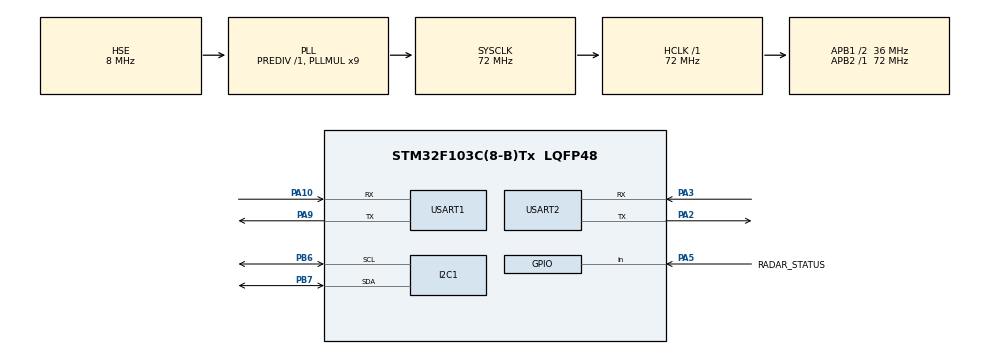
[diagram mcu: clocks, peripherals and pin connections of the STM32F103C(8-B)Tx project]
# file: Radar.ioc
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I2C1.I2C_Mode=I2C_Fast
Mcu.Family=STM32F1
Mcu.Name=STM32F103C(8-B)Tx
Mcu.Package=LQFP48
NVIC.PriorityGroup=NVIC_PRIORITYGROUP_4
NVIC.USART2_IRQn=true\:0\:0\:false\:false\:true\:true\:true\:true
PA10.Mode=Asynchronous
PA10.Signal=USART1_RX
PA13.Mode=Serial_Wire
PA13.Signal=SYS_JTMS-SWDIO
PA14.Mode=Serial_Wire
PA14.Signal=SYS_JTCK-SWCLK
PA2.Mode=Asynchronous
PA2.Signal=USART2_TX
PA3.Mode=Asynchronous
PA3.Signal=USART2_RX
PA5.GPIO_Label=RADAR_STATUS
PA5.GPIO_PuPd=GPIO_PULLDOWN
PA5.Signal=GPIO_Input
PA9.Mode=Asynchronous
PA9.Signal=USART1_TX
PB6.Mode=I2C
PB6.Signal=I2C1_SCL
PB7.Mode=I2C
PB7.Signal=I2C1_SDA
PD0-OSC_IN.Mode=HSE-External-Oscillator
PD0-OSC_IN.Signal=RCC_OSC_IN
PD1-OSC_OUT.Mode=HSE-External-Oscillator
PD1-OSC_OUT.Signal=RCC_OSC_OUT
ProjectManager.HeapSize=0x200
ProjectManager.StackSize=0x400
ProjectManager.TargetToolchain=CMake
RCC.AHBFreq_Value=72000000
RCC.APB1CLKDivider=RCC_HCLK_DIV2
RCC.APB1Freq_Value=36000000
RCC.APB1TimFreq_Value=72000000
RCC.APB2Freq_Value=72000000
RCC.APB2TimFreq_Value=72000000
RCC.HCLKFreq_Value=72000000
RCC.PLLMUL=RCC_PLL_MUL9
RCC.PLLSourceVirtual=RCC_PLLSOURCE_HSE
RCC.SYSCLKFreq_VALUE=72000000
RCC.SYSCLKSource=RCC_SYSCLKSOURCE_PLLCLK
RCC.USBFreq_Value=72000000
USART1.VirtualMode=VM_ASYNC
USART2.VirtualMode=VM_ASYNC
board=custom

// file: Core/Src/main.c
/* USER CODE BEGIN Header */
/**
  ******************************************************************************
  * @file           : main.c
  * @brief          : Main program body
  ******************************************************************************
  * @attention
  *
  * Copyright (c) 2026 STMicroelectronics.
  * All rights reserved.
  *
  * This software is licensed under terms that can be found in the LICENSE file
  * in the root directory of this software component.
  * If no LICENSE file comes with this software, it is provided AS-IS.
  *
  ******************************************************************************
  */
/* USER CODE END Header */
#include "main.h"

/* USER CODE BEGIN Includes */
#include "alert_led.h"
#include "oled_ui.h"
#include "radar_service.h"
#include "uart1_summary.h"
/* USER CODE END Includes */

I2C_HandleTypeDef hi2c1;

UART_HandleTypeDef huart1;
UART_HandleTypeDef huart2;

/* USER CODE BEGIN PV */
/* 雷达业务共享状态（雷达解析/OLED/UART1 汇总共用）。 */
static RadarAppState s_radar_state;
/* USER CODE END PV */

void SystemClock_Config(void);
static void MX_GPIO_Init(void);
static void MX_I2C1_Init(void);
static void MX_USART1_UART_Init(void);
static void MX_USART2_UART_Init(void);

int main(void)
{

  /* MCU Configuration--------------------------------------------------------*/

  /* Reset of all peripherals, Initializes the Flash interface and the Systick. */
  HAL_Init();

  /* Configure the system clock */
  SystemClock_Config();

  /* Initialize all configured peripherals */
  MX_GPIO_Init();
  MX_I2C1_Init();
  MX_USART1_UART_Init();
  MX_USART2_UART_Init();
  /* USER CODE BEGIN 2 */
  Radar_AppStateInit(&s_radar_state);

  OLED_UI_Init(&s_radar_state);
  UART1_Summary_Init(&huart1);
  Radar_Init(&huart2, &s_radar_state);
  AlertLed_Init();
  /* USER CODE END 2 */

  /* Infinite loop */
  while (1)
  {

    /* USER CODE BEGIN 3 */
    /* 1) 保障 UART2 中断接收链路持续在线。 */
    Radar_ServiceUart2RxRecovery();

    /* 2) 处理雷达帧并更新业务状态。 */
    Radar_ProcessFrames();
    Radar_ServiceOnlineTimeout();

    /* 3) 基于业务状态驱动告警灯。 */
    AlertLed_Service(&s_radar_state);

    /* 4) 刷新 OLED 波形与状态文本。 */
    OLED_UI_Service(&s_radar_state);

    /* 5) 向 UART1 输出摘要数据。 */
    UART1_Summary_Service(&s_radar_state);
    /* USER CODE END 3 */
  }
  /* USER CODE END 3 */
}

void SystemClock_Config(void)
{
  RCC_OscInitTypeDef RCC_OscInitStruct = {0};
  RCC_ClkInitTypeDef RCC_ClkInitStruct = {0};

  /** Initializes the RCC Oscillators according to the specified parameters
  * in the RCC_OscInitTypeDef structure.
  */
  RCC_OscInitStruct.OscillatorType = RCC_OSCILLATORTYPE_HSE;
  RCC_OscInitStruct.HSEState = RCC_HSE_ON;
  RCC_OscInitStruct.HSEPredivValue = RCC_HSE_PREDIV_DIV1;
  RCC_OscInitStruct.HSIState = RCC_HSI_ON;
  RCC_OscInitStruct.PLL.PLLState = RCC_PLL_ON;
  RCC_OscInitStruct.PLL.PLLSource = RCC_PLLSOURCE_HSE;
  RCC_OscInitStruct.PLL.PLLMUL = RCC_PLL_MUL9;
  if (HAL_RCC_OscConfig(&RCC_OscInitStruct) != HAL_OK)
  {
    Error_Handler();
  }

  /** Initializes the CPU, AHB and APB buses clocks
  */
  RCC_ClkInitStruct.ClockType = RCC_CLOCKTYPE_HCLK | RCC_CLOCKTYPE_SYSCLK
                              | RCC_CLOCKTYPE_PCLK1 | RCC_CLOCKTYPE_PCLK2;
  RCC_ClkInitStruct.SYSCLKSource = RCC_SYSCLKSOURCE_PLLCLK;
  RCC_ClkInitStruct.AHBCLKDivider = RCC_SYSCLK_DIV1;
  RCC_ClkInitStruct.APB1CLKDivider = RCC_HCLK_DIV2;
  RCC_ClkInitStruct.APB2CLKDivider = RCC_HCLK_DIV1;

  if (HAL_RCC_ClockConfig(&RCC_ClkInitStruct, FLASH_LATENCY_2) != HAL_OK)
  {
    Error_Handler();
  }
}

static void MX_I2C1_Init(void)
{

  hi2c1.Instance = I2C1;
  hi2c1.Init.ClockSpeed = 400000;
  hi2c1.Init.DutyCycle = I2C_DUTYCYCLE_2;
  hi2c1.Init.OwnAddress1 = 0;
  hi2c1.Init.AddressingMode = I2C_ADDRESSINGMODE_7BIT;
  hi2c1.Init.DualAddressMode = I2C_DUALADDRESS_DISABLE;
  hi2c1.Init.OwnAddress2 = 0;
  hi2c1.Init.GeneralCallMode = I2C_GENERALCALL_DISABLE;
  hi2c1.Init.NoStretchMode = I2C_NOSTRETCH_DISABLE;
  if (HAL_I2C_Init(&hi2c1) != HAL_OK)
  {
    Error_Handler();
  }
}

static void MX_USART1_UART_Init(void)
{

  huart1.Instance = USART1;
  huart1.Init.BaudRate = 115200;
  huart1.Init.WordLength = UART_WORDLENGTH_8B;
  huart1.Init.StopBits = UART_STOPBITS_1;
  huart1.Init.Parity = UART_PARITY_NONE;
  huart1.Init.Mode = UART_MODE_TX_RX;
  huart1.Init.HwFlowCtl = UART_HWCONTROL_NONE;
  huart1.Init.OverSampling = UART_OVERSAMPLING_16;
  if (HAL_UART_Init(&huart1) != HAL_OK)
  {
    Error_Handler();
  }
}

static void MX_USART2_UART_Init(void)
{

  huart2.Instance = USART2;
  huart2.Init.BaudRate = 115200;
  huart2.Init.WordLength = UART_WORDLENGTH_8B;
  huart2.Init.StopBits = UART_STOPBITS_1;
  huart2.Init.Parity = UART_PARITY_NONE;
  huart2.Init.Mode = UART_MODE_TX_RX;
  huart2.Init.HwFlowCtl = UART_HWCONTROL_NONE;
  huart2.Init.OverSampling = UART_OVERSAMPLING_16;
  if (HAL_UART_Init(&huart2) != HAL_OK)
  {
    Error_Handler();
  }
}

static void MX_GPIO_Init(void)
{
  GPIO_InitTypeDef GPIO_InitStruct = {0};

  /* GPIO Ports Clock Enable */
  __HAL_RCC_GPIOD_CLK_ENABLE();
  __HAL_RCC_GPIOA_CLK_ENABLE();
  __HAL_RCC_GPIOB_CLK_ENABLE();
  __HAL_RCC_GPIOC_CLK_ENABLE();

  /* 默认关闭告警灯。 */
  if (ALERT_LED_ACTIVE_LOW != 0U)
  {
    HAL_GPIO_WritePin(ALERT_LED_GPIO_Port, ALERT_LED_Pin, GPIO_PIN_SET);
  }
  else
  {
    HAL_GPIO_WritePin(ALERT_LED_GPIO_Port, ALERT_LED_Pin, GPIO_PIN_RESET);
  }

  /* 配置告警灯引脚为推挽输出。 */
  GPIO_InitStruct.Pin = ALERT_LED_Pin;
  GPIO_InitStruct.Mode = GPIO_MODE_OUTPUT_PP;
  GPIO_InitStruct.Pull = GPIO_NOPULL;
  GPIO_InitStruct.Speed = GPIO_SPEED_FREQ_LOW;
  HAL_GPIO_Init(ALERT_LED_GPIO_Port, &GPIO_InitStruct);

  /*Configure GPIO pin : RADAR_STATUS_Pin */
  GPIO_InitStruct.Pin = RADAR_STATUS_Pin;
  GPIO_InitStruct.Mode = GPIO_MODE_INPUT;
  GPIO_InitStruct.Pull = GPIO_PULLDOWN;
  HAL_GPIO_Init(RADAR_STATUS_GPIO_Port, &GPIO_InitStruct);

}

/* USER CODE BEGIN 4 */
void HAL_UART_RxCpltCallback(UART_HandleTypeDef *huart)
{
  Radar_UartRxCpltCallback(huart);
}

void HAL_UART_ErrorCallback(UART_HandleTypeDef *huart)
{
  Radar_UartErrorCallback(huart);
}
/* USER CODE END 4 */

void Error_Handler(void)
{
  __disable_irq();
  while (1)
  {
  }
}
